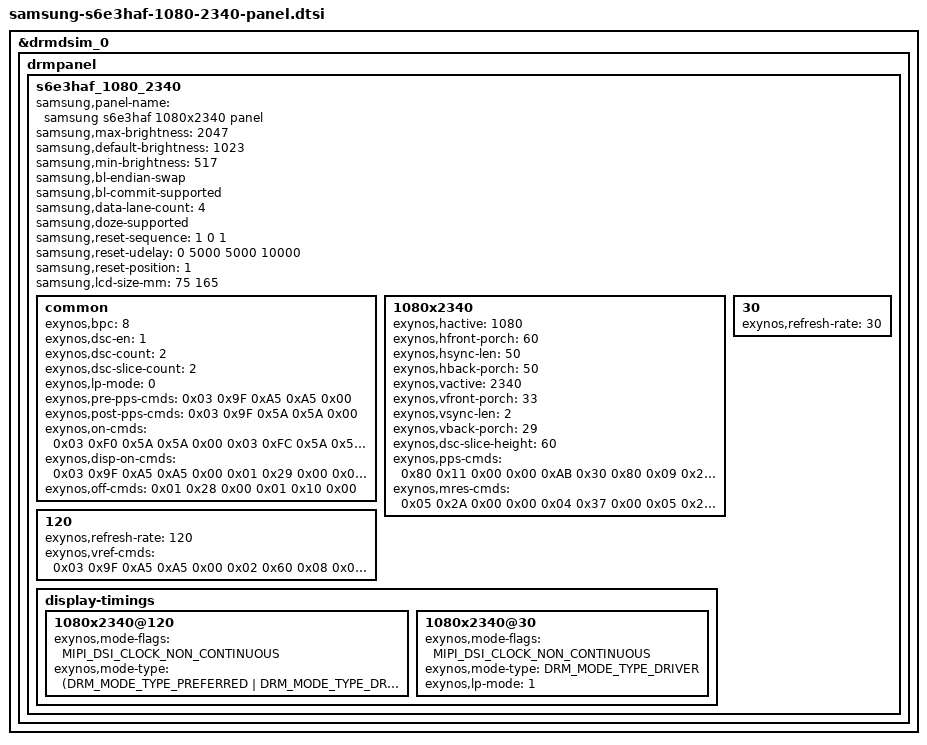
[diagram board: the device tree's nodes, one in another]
#include <dt-bindings/display/exynos-display.h>
#include <dt-bindings/display/exynos-mipi-display.h>

&drmdsim_0 {
	drmpanel {
		s6e3haf_1080_2340: s6e3haf_1080_2340 {
			samsung,panel-name = "samsung s6e3haf 1080x2340 panel";

			samsung,max-brightness = <2047>;
			samsung,default-brightness = <1023>;
			samsung,min-brightness = <517>;
			samsung,bl-endian-swap;
			samsung,bl-commit-supported;

			samsung,data-lane-count = <4>;
			samsung,doze-supported;

			samsung,reset-sequence = <1 0 1>;
			samsung,reset-udelay = <0 5000 5000 10000>;
			samsung,reset-position = <1>;

			samsung,lcd-size-mm = <75 165>; /* width x height */

			/* common info & cmds */
			common {
				exynos,bpc = <8>;
				exynos,dsc-en = <1>;
				exynos,dsc-count = <2>;
				exynos,dsc-slice-count = <2>;

				exynos,lp-mode = <0>;

				exynos,pre-pps-cmds = <
					0x03 0x9F 0xA5 0xA5 0x00 /* PASSWD0 UNLOCK */
					>;
				exynos,post-pps-cmds = <
					0x03 0x9F 0x5A 0x5A 0x00 /* PASSWD0 LOCK */
					>;
				exynos,on-cmds = <
					0x03 0xF0 0x5A 0x5A 0x00
					0x03 0xFC 0x5A 0x5A 0x00
					/* sleep out: 200ms delay */
					0x01 0x11 0xC8
					/* Typical high duration */
					0x0A 0xB9 0x00 0x0C 0x8C 0x00 0x09 0x00 0x00 0x00 0x00 0x00
					/*  enable brightness control */
					0x02 0x53 0x20 0x00

					/* WRDISBV(51h) = 1st[7:0], 2nd[15:8] */
					0x03 0x51 0xFF 0x7F 0x00

					/* TE on */
					0x01 0x35 0x00

					/* ESD flag: [2]=VLIN3, [6]=VLIN1 error check */
					0x03 0xED 0x04 0x44 0x00

					/* SEQ_FFC */
					/* 0x0D 0xC5 0x09 0x10 0x68 0x45 0x3B 0x9A 0x3B 0x9A 0x3B 0x9A 0x3B 0x9A 0x00 */
					>;
				exynos,disp-on-cmds = <
					0x03 0x9F 0xA5 0xA5 0x00 /* PASSWD0 UNLOCK */
					0x01 0x29 0x00
					0x03 0x9F 0x5A 0x5A 0x00 /* PASSWD0 LOCK */
					>;
				exynos,off-cmds = <
					0x01 0x28 0x00
					0x01 0x10 0x00
					>;
			};
			/* resolution dependent info & cmds */
			1080x2340 {
				exynos,hactive = <1080>;
				exynos,hfront-porch = <60>;
				exynos,hsync-len = <50>;
				exynos,hback-porch = <50>;
				exynos,vactive = <2340>;
				exynos,vfront-porch = <33>;
				exynos,vsync-len = <2>;
				exynos,vback-porch = <29>;

				exynos,dsc-slice-height = <60>;

				exynos,pps-cmds = <
					0x80
					0x11 0x00 0x00 0xAB 0x30 0x80 0x09 0x24 0x04 0x38
					0x00 0x3C 0x02 0x1C 0x02 0x1C 0x02 0x00 0x02 0x0E
					0x00 0x20 0x05 0xD2 0x00 0x07 0x00 0x0C 0x01 0xA1
					0x01 0xB2 0x18 0x00 0x10 0xF0 0x07 0x10 0x20 0x00
					0x06 0x0F 0x0F 0x33 0x0E 0x1C 0x2A 0x38 0x46 0x54
					0x62 0x69 0x70 0x77 0x79 0x7B 0x7D 0x7E 0x01 0x02
					0x22 0x00 0x2A 0x40 0x2A 0xBE 0x3A 0xFC 0x3A 0xFA
					0x3A 0xF8 0x3B 0x38 0x3B 0x78 0x3B 0xB6 0x4B 0xF6
					0x4C 0x34 0x4C 0x74 0x5C 0x74 0x8C 0xF4 0x00 0x00
					0x00 0x00 0x00 0x00 0x00 0x00 0x00 0x00 0x00 0x00
					0x00 0x00 0x00 0x00 0x00 0x00 0x00 0x00 0x00 0x00
					0x00 0x00 0x00 0x00 0x00 0x00 0x00 0x00 0x00 0x00
					0x00 0x00 0x00 0x00 0x00 0x00 0x00 0x00
					>;

				exynos,mres-cmds = <
					0x05 0x2A 0x00 0x00 0x04 0x37 0x00
					0x05 0x2B 0x00 0x00 0x09 0x23 0x00
					0x03 0xF0 0x5A 0x5A 0x00
					0x02 0xBA 0x02 0x00
					0x03 0xF0 0xA5 0xA5 0x00
					>;
			};

			/* framerate dependent info & cmds */
			30 {
				exynos,refresh-rate = <30>;
			};
			120 {
				exynos,refresh-rate = <120>;
				exynos,vref-cmds = <
					0x03 0x9F 0xA5 0xA5 0x00
					0x02 0x60 0x08 0x00
					0x03 0x9F 0x5A 0x5A 0x00
					0x04 0xB0 0x00 0x0D 0xF2 0x00
					0x03 0xF2 0x00 0x10 0x00
					0x02 0xF7 0x0F 0x00
					0x03 0xF0 0xA5 0xA5 0x00
					>;
			};

			display-timings {
				/*
				* The exynos properties can be declared repeatedly in any node.
				* The properties of child nodes have a high priority
				* than properties of parent node.
				*/
				1080x2340@120 {
					exynos,mode-flags = <MIPI_DSI_CLOCK_NON_CONTINUOUS>;
					exynos,mode-type = <(DRM_MODE_TYPE_PREFERRED |
                                                             DRM_MODE_TYPE_DRIVER)>;
				};
				1080x2340@30 {
					exynos,mode-flags = <MIPI_DSI_CLOCK_NON_CONTINUOUS>;
					exynos,mode-type = <DRM_MODE_TYPE_DRIVER>;
					exynos,lp-mode = <1>;

					/* add switching & vref cmds */
				};
			};
		};
	};
};
